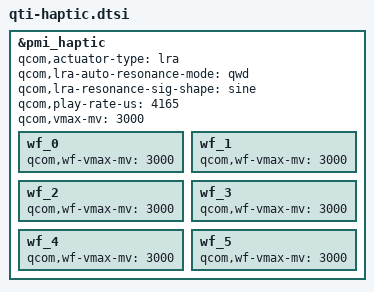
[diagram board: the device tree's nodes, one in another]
/* Haptics */
&pmi_haptic{
	qcom,actuator-type = "lra";
	qcom,lra-auto-resonance-mode = "qwd";
	qcom,lra-resonance-sig-shape = "sine";
//	qcom,lra-high-z="opt1";
//	qcom,lra-res-cal-period = <4>;
//	qcom,misc-trim-error-rc19p2-clk-reg-present;
//	qcom,brake-pattern = [03 02 01 00];
	qcom,play-rate-us = <4165>;
	qcom,vmax-mv = <3000>;
	wf_0 { qcom,wf-vmax-mv = <3000>; };
	wf_1 { qcom,wf-vmax-mv = <3000>; };
	wf_2 { qcom,wf-vmax-mv = <3000>; };
	wf_3 { qcom,wf-vmax-mv = <3000>; };
	wf_4 { qcom,wf-vmax-mv = <3000>; };
	wf_5 { qcom,wf-vmax-mv = <3000>; };
};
